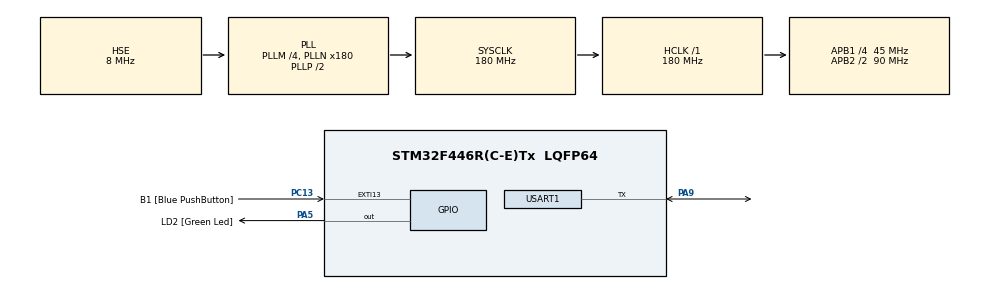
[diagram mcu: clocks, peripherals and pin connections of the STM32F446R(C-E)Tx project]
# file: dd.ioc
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Dma.Request0=USART1_RX
Dma.Request1=USART1_TX
Dma.USART1_RX.0.Direction=DMA_PERIPH_TO_MEMORY
Dma.USART1_RX.0.FIFOMode=DMA_FIFOMODE_DISABLE
Dma.USART1_RX.0.Instance=DMA2_Stream2
Dma.USART1_RX.0.MemDataAlignment=DMA_MDATAALIGN_BYTE
Dma.USART1_RX.0.MemInc=DMA_MINC_ENABLE
Dma.USART1_RX.0.Mode=DMA_NORMAL
Dma.USART1_RX.0.PeriphDataAlignment=DMA_PDATAALIGN_BYTE
Dma.USART1_RX.0.PeriphInc=DMA_PINC_DISABLE
Dma.USART1_RX.0.Priority=DMA_PRIORITY_LOW
Dma.USART1_TX.1.Direction=DMA_MEMORY_TO_PERIPH
Dma.USART1_TX.1.FIFOMode=DMA_FIFOMODE_DISABLE
Dma.USART1_TX.1.Instance=DMA2_Stream7
Dma.USART1_TX.1.MemDataAlignment=DMA_MDATAALIGN_BYTE
Dma.USART1_TX.1.MemInc=DMA_MINC_ENABLE
Dma.USART1_TX.1.Mode=DMA_NORMAL
Dma.USART1_TX.1.PeriphDataAlignment=DMA_PDATAALIGN_BYTE
Dma.USART1_TX.1.PeriphInc=DMA_PINC_DISABLE
Dma.USART1_TX.1.Priority=DMA_PRIORITY_LOW
Mcu.Family=STM32F4
Mcu.Name=STM32F446R(C-E)Tx
Mcu.Package=LQFP64
NVIC.DMA2_Stream2_IRQn=true\:0\:0\:false\:false\:true\:false\:true\:true
NVIC.DMA2_Stream7_IRQn=true\:0\:0\:false\:false\:true\:false\:true\:true
NVIC.PriorityGroup=NVIC_PRIORITYGROUP_0
NVIC.USART1_IRQn=true\:0\:0\:false\:false\:true\:true\:true\:true
PA13.GPIO_Label=TMS
PA13.Mode=Serial_Wire
PA13.Signal=SYS_JTMS-SWDIO
PA14.GPIO_Label=TCK
PA14.Mode=Serial_Wire
PA14.Signal=SYS_JTCK-SWCLK
PA2.GPIO_Label=USART_TX
PA2.Signal=USART2_TX
PA3.GPIO_Label=USART_RX
PA3.Signal=USART2_RX
PA5.GPIO_Label=LD2 [Green Led]
PA5.Signal=GPIO_Output
PA9.Mode=Half_duplex(single_wire_mode)
PA9.Signal=USART1_TX
PB3.GPIO_Label=SWO
PB3.Signal=SYS_JTDO-SWO
PC13.GPIO_Label=B1 [Blue PushButton]
PC13.GPIO_ModeDefaultEXTI=GPIO_MODE_IT_FALLING
PC13.Signal=GPXTI13
PC14-OSC32_IN.Signal=RCC_OSC32_IN
PC15-OSC32_OUT.Signal=RCC_OSC32_OUT
PH0-OSC_IN.Mode=HSE-External-Clock-Source
PH0-OSC_IN.Signal=RCC_OSC_IN
PH1-OSC_OUT.Mode=HSE-External-Clock-Source
PH1-OSC_OUT.Signal=RCC_OSC_OUT
ProjectManager.HeapSize=0x200
ProjectManager.StackSize=0x400
ProjectManager.TargetToolchain=STM32CubeIDE
RCC.48MHZClocksFreq_Value=84000000
RCC.AHBFreq_Value=180000000
RCC.APB1CLKDivider=RCC_HCLK_DIV4
RCC.APB1Freq_Value=45000000
RCC.APB1TimFreq_Value=90000000
RCC.APB2CLKDivider=RCC_HCLK_DIV2
RCC.APB2Freq_Value=90000000
RCC.APB2TimFreq_Value=180000000
RCC.CortexFreq_Value=180000000
RCC.FLatency-AdvancedSettings=FLASH_LATENCY_5
RCC.HCLKFreq_Value=180000000
RCC.HSE_VALUE=8000000
RCC.HSI_VALUE=16000000
RCC.PLLM=4
RCC.PLLN=180
RCC.PLLSourceVirtual=RCC_PLLSOURCE_HSE
RCC.SYSCLKFreq_VALUE=180000000
RCC.SYSCLKSource=RCC_SYSCLKSOURCE_PLLCLK
RCC.USBFreq_Value=180000000
RCC.VCOOutputFreq_Value=360000000
USART1.BaudRate=9600
USART1.VirtualMode=VM_ASYNC
board=NUCLEO-F446RE

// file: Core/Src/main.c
/* USER CODE BEGIN Header */
/**
  ******************************************************************************
  * @file           : main.c
  * @brief          : Main program body
  ******************************************************************************
  * @attention
  *
  * Copyright (c) 2024 STMicroelectronics.
  * All rights reserved.
  *
  * This software is licensed under terms that can be found in the LICENSE file
  * in the root directory of this software component.
  * If no LICENSE file comes with this software, it is provided AS-IS.
  *
  ******************************************************************************
  */
/* USER CODE END Header */
#include "main.h"

UART_HandleTypeDef huart1;
DMA_HandleTypeDef hdma_usart1_rx;
DMA_HandleTypeDef hdma_usart1_tx;

void SystemClock_Config(void);
static void MX_GPIO_Init(void);
static void MX_DMA_Init(void);
static void MX_USART1_UART_Init(void);

/* USER CODE BEGIN 0 */

int presense = 0;
int isRxed = 0;
uint8_t RxData[8], Temp_LSB = 0, Temp_MSB = 0;
uint16_t Temp = 0;
float Temperature = -99;

void uart_init(uint32_t baud){
		huart1.Instance = USART1;
		huart1.Init.BaudRate = baud;
		huart1.Init.WordLength = UART_WORDLENGTH_8B;
		huart1.Init.StopBits = UART_STOPBITS_1;
		huart1.Init.Parity = UART_PARITY_NONE;
		huart1.Init.Mode = UART_MODE_TX_RX;
		huart1.Init.HwFlowCtl = UART_HWCONTROL_NONE;
		huart1.Init.OverSampling = UART_OVERSAMPLING_16;
		if (HAL_HalfDuplex_Init(&huart1) != HAL_OK) {
			Error_Handler();
		}
}

int DS18B20_Start(void){
	  //HAL_UART_DeInit(&huart1);
	  //HAL_Delay(2000);
	  uint8_t data = 0xF0;

	  uart_init(9600);
	  HAL_UART_Transmit(&huart1, &data, 1, 100);
	  int value = HAL_UART_Receive(&huart1, &data, 1, 3000);
	  if (value != HAL_OK) return -1;
	  uart_init(115200);
	  if (data == 0xf0) return -2;
	  return 1;
}

void DS18B20_Write(uint8_t data){
	uint8_t buffer[8];
	for (int i=0; i<8; i++)
	{
		if ((data & (1<<i)) != 0)
		{
			buffer[i] = 0xFF;
		}
		else
		{
			buffer[i] = 0x00;
		}
	}

	HAL_UART_Transmit(&huart1, buffer, 8, 100);
}

uint8_t DS18B20_Read()
{
	uint8_t buffer[8];
	uint8_t value = 0;
	for (int i=0; i<8; i++){
		buffer[i] = 0xFF;
	}

	HAL_UART_Transmit_DMA(&huart1, buffer, 8);
	HAL_UART_Receive_DMA(&huart1, RxData, 8);

	while (isRxed == 0);

	for (int i=0; i<8; i++){
		if (RxData[i] == 0xFF){
			value |= 1<<i;
		}
	}

	isRxed = 0;

	return value;
}

void HAL_UART_RxCpltCallback(UART_HandleTypeDef *huart){
	isRxed = 1;
}

/* USER CODE END 0 */

int main(void)
{

  /* MCU Configuration--------------------------------------------------------*/

  /* Reset of all peripherals, Initializes the Flash interface and the Systick. */
  HAL_Init();

  /* Configure the system clock */
  SystemClock_Config();

  /* Initialize all configured peripherals */
  MX_GPIO_Init();
  MX_DMA_Init();
  MX_USART1_UART_Init();

  /* Infinite loop */
  while (1)
  {

    /* USER CODE BEGIN 3 */

	  presense = DS18B20_Start();
	  DS18B20_Write(0xCC);
	  DS18B20_Write(0x44);

	  presense = DS18B20_Start();
	  DS18B20_Write(0xCC);
	  DS18B20_Write(0xBE);

	  Temp_LSB = DS18B20_Read();
	  Temp_MSB = DS18B20_Read();
	  Temp = (Temp_MSB<<8) | Temp_LSB;
	  Temperature = (float)Temp/16.0;
	  HAL_Delay(2000);
  }
  /* USER CODE END 3 */
}

void SystemClock_Config(void)
{
  RCC_OscInitTypeDef RCC_OscInitStruct = {0};
  RCC_ClkInitTypeDef RCC_ClkInitStruct = {0};

  /** Configure the main internal regulator output voltage
  */
  __HAL_RCC_PWR_CLK_ENABLE();
  __HAL_PWR_VOLTAGESCALING_CONFIG(PWR_REGULATOR_VOLTAGE_SCALE1);

  /** Initializes the RCC Oscillators according to the specified parameters
  * in the RCC_OscInitTypeDef structure.
  */
  RCC_OscInitStruct.OscillatorType = RCC_OSCILLATORTYPE_HSE;
  RCC_OscInitStruct.HSEState = RCC_HSE_BYPASS;
  RCC_OscInitStruct.PLL.PLLState = RCC_PLL_ON;
  RCC_OscInitStruct.PLL.PLLSource = RCC_PLLSOURCE_HSE;
  RCC_OscInitStruct.PLL.PLLM = 4;
  RCC_OscInitStruct.PLL.PLLN = 180;
  RCC_OscInitStruct.PLL.PLLP = RCC_PLLP_DIV2;
  RCC_OscInitStruct.PLL.PLLQ = 2;
  RCC_OscInitStruct.PLL.PLLR = 2;
  if (HAL_RCC_OscConfig(&RCC_OscInitStruct) != HAL_OK)
  {
    Error_Handler();
  }

  /** Activate the Over-Drive mode
  */
  if (HAL_PWREx_EnableOverDrive() != HAL_OK)
  {
    Error_Handler();
  }

  /** Initializes the CPU, AHB and APB buses clocks
  */
  RCC_ClkInitStruct.ClockType = RCC_CLOCKTYPE_HCLK|RCC_CLOCKTYPE_SYSCLK
                              |RCC_CLOCKTYPE_PCLK1|RCC_CLOCKTYPE_PCLK2;
  RCC_ClkInitStruct.SYSCLKSource = RCC_SYSCLKSOURCE_PLLCLK;
  RCC_ClkInitStruct.AHBCLKDivider = RCC_SYSCLK_DIV1;
  RCC_ClkInitStruct.APB1CLKDivider = RCC_HCLK_DIV4;
  RCC_ClkInitStruct.APB2CLKDivider = RCC_HCLK_DIV2;

  if (HAL_RCC_ClockConfig(&RCC_ClkInitStruct, FLASH_LATENCY_5) != HAL_OK)
  {
    Error_Handler();
  }
}

static void MX_USART1_UART_Init(void)
{

  huart1.Instance = USART1;
  huart1.Init.BaudRate = 9600;
  huart1.Init.WordLength = UART_WORDLENGTH_8B;
  huart1.Init.StopBits = UART_STOPBITS_1;
  huart1.Init.Parity = UART_PARITY_NONE;
  huart1.Init.Mode = UART_MODE_TX_RX;
  huart1.Init.HwFlowCtl = UART_HWCONTROL_NONE;
  huart1.Init.OverSampling = UART_OVERSAMPLING_16;
  if (HAL_HalfDuplex_Init(&huart1) != HAL_OK)
  {
    Error_Handler();
  }

}

static void MX_DMA_Init(void)
{

  /* DMA controller clock enable */
  __HAL_RCC_DMA2_CLK_ENABLE();

  /* DMA interrupt init */
  /* DMA2_Stream2_IRQn interrupt configuration */
  HAL_NVIC_SetPriority(DMA2_Stream2_IRQn, 0, 0);
  HAL_NVIC_EnableIRQ(DMA2_Stream2_IRQn);
  /* DMA2_Stream7_IRQn interrupt configuration */
  HAL_NVIC_SetPriority(DMA2_Stream7_IRQn, 0, 0);
  HAL_NVIC_EnableIRQ(DMA2_Stream7_IRQn);

}

static void MX_GPIO_Init(void)
{
  GPIO_InitTypeDef GPIO_InitStruct = {0};

  /* GPIO Ports Clock Enable */
  __HAL_RCC_GPIOC_CLK_ENABLE();
  __HAL_RCC_GPIOH_CLK_ENABLE();
  __HAL_RCC_GPIOA_CLK_ENABLE();
  __HAL_RCC_GPIOB_CLK_ENABLE();

  /*Configure GPIO pin Output Level */
  HAL_GPIO_WritePin(LD2_GPIO_Port, LD2_Pin, GPIO_PIN_RESET);

  /*Configure GPIO pin : B1_Pin */
  GPIO_InitStruct.Pin = B1_Pin;
  GPIO_InitStruct.Mode = GPIO_MODE_IT_FALLING;
  GPIO_InitStruct.Pull = GPIO_NOPULL;
  HAL_GPIO_Init(B1_GPIO_Port, &GPIO_InitStruct);

  /*Configure GPIO pins : USART_TX_Pin USART_RX_Pin */
  GPIO_InitStruct.Pin = USART_TX_Pin|USART_RX_Pin;
  GPIO_InitStruct.Mode = GPIO_MODE_AF_PP;
  GPIO_InitStruct.Pull = GPIO_NOPULL;
  GPIO_InitStruct.Speed = GPIO_SPEED_FREQ_VERY_HIGH;
  GPIO_InitStruct.Alternate = GPIO_AF7_USART2;
  HAL_GPIO_Init(GPIOA, &GPIO_InitStruct);

  /*Configure GPIO pin : LD2_Pin */
  GPIO_InitStruct.Pin = LD2_Pin;
  GPIO_InitStruct.Mode = GPIO_MODE_OUTPUT_PP;
  GPIO_InitStruct.Pull = GPIO_NOPULL;
  GPIO_InitStruct.Speed = GPIO_SPEED_FREQ_LOW;
  HAL_GPIO_Init(LD2_GPIO_Port, &GPIO_InitStruct);

}

void Error_Handler(void)
{
  __disable_irq();
  while (1)
  {
  }
}
